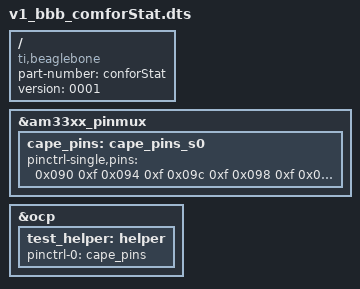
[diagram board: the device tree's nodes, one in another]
/dts-v1/;
/plugin/;
 
/ {
    compatible = "ti,beaglebone", "ti,beaglebone-black";
 
    /* identification */
    part-number = "conforStat";
    version = "0001";

    fragment@0 {
        target = <&am33xx_pinmux>;
        __overlay__ {
            cape_pins: cape_pins_s0 {
                pinctrl-single,pins = <
                    /* P8 */
                    0x090 0xf
                    0x094 0xf
                    0x09c 0xf
                    0x098 0xf
                    0x024 0x27
                    /* P9 */
                    0x154 0xf
                    0x150 0xf
                >;
            };
        };
    };
 
    fragment@1 {
        target = <&ocp>;
        __overlay__ {
             test_helper: helper {
              status = "okay";
              pinctrl-names = "default";
              pinctrl-0 = <&cape_pins>;
             }; 
        };
    };
};
